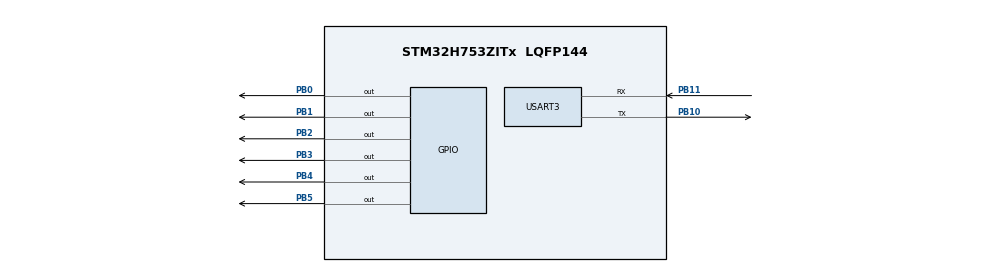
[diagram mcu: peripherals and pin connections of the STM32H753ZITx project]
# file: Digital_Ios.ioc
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CORTEX_M7.CPU_DCache=Disabled
CORTEX_M7.CPU_ICache=Disabled
CORTEX_M7.MPU_Control=__NULL
CORTEX_M7.default_mode_Activation=1
Mcu.Family=STM32H7
Mcu.Name=STM32H753ZITx
Mcu.Package=LQFP144
NVIC.PriorityGroup=NVIC_PRIORITYGROUP_4
PB0.Signal=GPIO_Output
PB0.TagName=LD1
PB1.Signal=GPIO_Output
PB10.Mode=Asynchronous
PB10.Signal=USART3_TX
PB11.Mode=Asynchronous
PB11.Signal=USART3_RX
PB14.TagName=LD3
PB2.Signal=GPIO_Output
PB3\ (JTDO/TRACESWO).Signal=GPIO_Output
PB4\ (NJTRST).Signal=GPIO_Output
PB5.Signal=GPIO_Output
PB7.TagName=LD2
PC13.TagName=BUTTON
PD8.TagName=VCP_TX
PD9.TagName=VCP_RX
ProjectManager.HeapSize=0x200
ProjectManager.StackSize=0x400
ProjectManager.TargetToolchain=STM32CubeIDE
RCC.ADCFreq_Value=129000000
RCC.APB1Freq_Value=64000000
RCC.APB2Freq_Value=64000000
RCC.APB3Freq_Value=64000000
RCC.APB4Freq_Value=64000000
RCC.CortexFreq_Value=64000000
RCC.DIVM1=1
RCC.DIVN1=24
RCC.DIVQ1=4
RCC.HCLKFreq_Value=64000000
RCC.HSE_VALUE=8000000
RCC.PLLFRACN=0
RCC.PWR_Regulator_Voltage_Scale=PWR_REGULATOR_VOLTAGE_SCALE2
RCC.SYSCLKFreq_VALUE=64000000
RCC.USBFreq_Value=384000000
USART3.VirtualMode-Asynchronous=VM_ASYNC
VP_MEMORYMAP_VS_MEMORYMAP.Mode=CurAppReg
board=NUCLEO-H753ZI

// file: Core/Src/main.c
/* USER CODE BEGIN Header */
/**
  ******************************************************************************
  * @file           : main.c
  * @brief          : Main program body
  ******************************************************************************
  * @attention
  *
  * Copyright (c) 2026 STMicroelectronics.
  * All rights reserved.
  *
  * This software is licensed under terms that can be found in the LICENSE file
  * in the root directory of this software component.
  * If no LICENSE file comes with this software, it is provided AS-IS.
  *
  ******************************************************************************
  */
/* USER CODE END Header */
#include "main.h"

/* USER CODE BEGIN Includes */
#include <string.h>
#include <stdio.h>
/* USER CODE END Includes */

UART_HandleTypeDef huart3;

void SystemClock_Config(void);
static void MX_GPIO_Init(void);
static void MX_USART3_UART_Init(void);

/* USER CODE BEGIN 0 */

static void UART_Print(char *msg)
{
  HAL_UART_Transmit(&huart3, (uint8_t *)msg, strlen(msg), HAL_MAX_DELAY);
}

/* Optional: enable printf() via USART3 */
//int _write(int file, char *ptr, int len)
//{
//  HAL_UART_Transmit(&huart3, (uint8_t *)ptr, len, HAL_MAX_DELAY);
//  return len;
//}

/* USER CODE END 0 */

int main(void)
{

  /* MCU Configuration--------------------------------------------------------*/

  /* Reset of all peripherals, Initializes the Flash interface and the Systick. */
  HAL_Init();

  /* Configure the system clock */
  SystemClock_Config();

  /* Initialize all configured peripherals */
  MX_GPIO_Init();
  MX_USART3_UART_Init();

  /* USER CODE BEGIN 2 */
  UART_Print("\r\n=== Digital IO Test (PB0–PB5) Started ===\r\n");
  UART_Print("USART3 @ 115200 baud\r\n");
  /* USER CODE END 2 */

  /* Infinite loop */

  /* USER CODE BEGIN WHILE */
  while (1)
  {
    /* Toggle PB0–PB5 */
    HAL_GPIO_TogglePin(GPIOB, GPIO_PIN_0);
    HAL_GPIO_TogglePin(GPIOB, GPIO_PIN_1);
    HAL_GPIO_TogglePin(GPIOB, GPIO_PIN_2);
    HAL_GPIO_TogglePin(GPIOB, GPIO_PIN_3);
    HAL_GPIO_TogglePin(GPIOB, GPIO_PIN_4);
    HAL_GPIO_TogglePin(GPIOB, GPIO_PIN_5);

    UART_Print("PB0–PB5 toggled\r\n");

    HAL_Delay(500);
  }
  /* USER CODE END WHILE */

  }

void SystemClock_Config(void)
{
  RCC_OscInitTypeDef RCC_OscInitStruct = {0};
  RCC_ClkInitTypeDef RCC_ClkInitStruct = {0};

  /** Supply configuration update enable
  */
  HAL_PWREx_ConfigSupply(PWR_LDO_SUPPLY);

  /** Configure the main internal regulator output voltage
  */
  __HAL_PWR_VOLTAGESCALING_CONFIG(PWR_REGULATOR_VOLTAGE_SCALE2);

  while(!__HAL_PWR_GET_FLAG(PWR_FLAG_VOSRDY)) {}

  /** Initializes the RCC Oscillators according to the specified parameters
  * in the RCC_OscInitTypeDef structure.
  */
  RCC_OscInitStruct.OscillatorType = RCC_OSCILLATORTYPE_HSI;
  RCC_OscInitStruct.HSIState = RCC_HSI_DIV1;
  RCC_OscInitStruct.HSICalibrationValue = RCC_HSICALIBRATION_DEFAULT;
  RCC_OscInitStruct.PLL.PLLState = RCC_PLL_NONE;
  if (HAL_RCC_OscConfig(&RCC_OscInitStruct) != HAL_OK)
  {
    Error_Handler();
  }

  /** Initializes the CPU, AHB and APB buses clocks
  */
  RCC_ClkInitStruct.ClockType = RCC_CLOCKTYPE_HCLK|RCC_CLOCKTYPE_SYSCLK
                              |RCC_CLOCKTYPE_PCLK1|RCC_CLOCKTYPE_PCLK2
                              |RCC_CLOCKTYPE_D3PCLK1|RCC_CLOCKTYPE_D1PCLK1;
  RCC_ClkInitStruct.SYSCLKSource = RCC_SYSCLKSOURCE_HSI;
  RCC_ClkInitStruct.SYSCLKDivider = RCC_SYSCLK_DIV1;
  RCC_ClkInitStruct.AHBCLKDivider = RCC_HCLK_DIV1;
  RCC_ClkInitStruct.APB3CLKDivider = RCC_APB3_DIV1;
  RCC_ClkInitStruct.APB1CLKDivider = RCC_APB1_DIV1;
  RCC_ClkInitStruct.APB2CLKDivider = RCC_APB2_DIV1;
  RCC_ClkInitStruct.APB4CLKDivider = RCC_APB4_DIV1;

  if (HAL_RCC_ClockConfig(&RCC_ClkInitStruct, FLASH_LATENCY_1) != HAL_OK)
  {
    Error_Handler();
  }
}

static void MX_USART3_UART_Init(void)
{

  huart3.Instance = USART3;
  huart3.Init.BaudRate = 115200;
  huart3.Init.WordLength = UART_WORDLENGTH_8B;
  huart3.Init.StopBits = UART_STOPBITS_1;
  huart3.Init.Parity = UART_PARITY_NONE;
  huart3.Init.Mode = UART_MODE_TX_RX;
  huart3.Init.HwFlowCtl = UART_HWCONTROL_NONE;
  huart3.Init.OverSampling = UART_OVERSAMPLING_16;
  huart3.Init.OneBitSampling = UART_ONE_BIT_SAMPLE_DISABLE;
  huart3.Init.ClockPrescaler = UART_PRESCALER_DIV1;
  huart3.AdvancedInit.AdvFeatureInit = UART_ADVFEATURE_NO_INIT;
  if (HAL_UART_Init(&huart3) != HAL_OK)
  {
    Error_Handler();
  }
  if (HAL_UARTEx_SetTxFifoThreshold(&huart3, UART_TXFIFO_THRESHOLD_1_8) != HAL_OK)
  {
    Error_Handler();
  }
  if (HAL_UARTEx_SetRxFifoThreshold(&huart3, UART_RXFIFO_THRESHOLD_1_8) != HAL_OK)
  {
    Error_Handler();
  }
  if (HAL_UARTEx_DisableFifoMode(&huart3) != HAL_OK)
  {
    Error_Handler();
  }

}

static void MX_GPIO_Init(void)
{
  GPIO_InitTypeDef GPIO_InitStruct = {0};

  /* GPIO Ports Clock Enable */
  __HAL_RCC_GPIOB_CLK_ENABLE();

  /*Configure GPIO pin Output Level */
  HAL_GPIO_WritePin(GPIOB, GPIO_PIN_0|GPIO_PIN_1|GPIO_PIN_2|GPIO_PIN_3
                          |GPIO_PIN_4|GPIO_PIN_5, GPIO_PIN_RESET);

  /*Configure GPIO pins : PB0 PB1 PB2 PB3
                           PB4 PB5 */
  GPIO_InitStruct.Pin = GPIO_PIN_0|GPIO_PIN_1|GPIO_PIN_2|GPIO_PIN_3
                          |GPIO_PIN_4|GPIO_PIN_5;
  GPIO_InitStruct.Mode = GPIO_MODE_OUTPUT_PP;
  GPIO_InitStruct.Pull = GPIO_NOPULL;
  GPIO_InitStruct.Speed = GPIO_SPEED_FREQ_LOW;
  HAL_GPIO_Init(GPIOB, &GPIO_InitStruct);

}

void Error_Handler(void)
{
  __disable_irq();
  while (1)
  {
  }
}
